# XN11EXXX register map
File version: 1.3
CPU: CM0 r0p0, little endian, no MPU, no FPU, 2 interrupt priority bits
Registers are 32-bit, read-write, reset 0x0 unless marked. A register's access mark holds for its fields unless they carry their own. Offsets are from the block's base; [hi:lo] are bit positions; {n}, {i} and the like mark numbered series.

## ADC — Analog-to-Digital Converter
Base 0x40020000
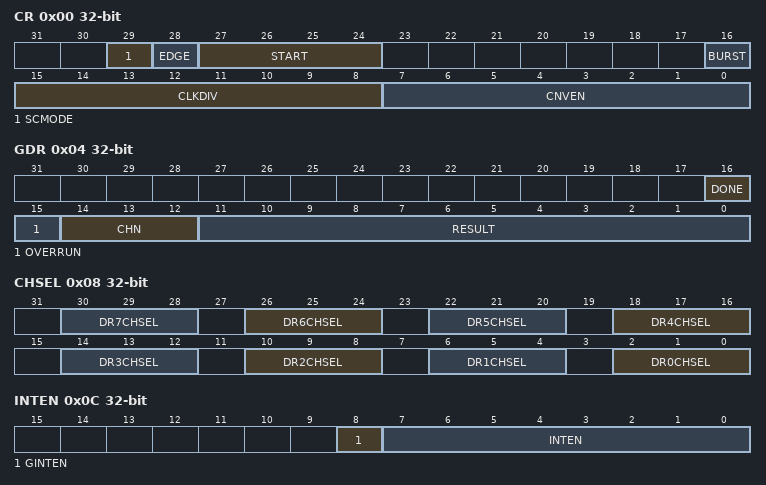
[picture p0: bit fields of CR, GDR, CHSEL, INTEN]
0x00 CR — ADC control register
  [29] SCMODE — ADC converter sample clock selection
  [28] EDGE — Start Edge control
  [27:24] START — Conversion starts control
  [16] BURST — Burst mode control
  [15:8] CLKDIV — APB clock (PCLK) divider
  [7:0] CNVEN — Enable ADC conversion value to DR0~DR7
0x04 GDR — ADC Global Data Register
  [16] DONE — This bit is set to 1 when an A/D conversion completes
  [15] OVERRUN — The conversion results has been overwritten
  [14:12] CHN — The ADC channel related to results
  [11:0] RESULT — Current ADC conversion results
0x08 CHSEL — Channel select control register
  [4n+2:4n] DR{n}CHSEL (n=0..7) — The conversion result is saved in DR{n} register
0x0C INTEN — ADC Interrupt Enable Register
  [8] GINTEN — enables the global DONE flag in ADC DR to generate an interrupt.
  [7:0] INTEN — These bits allow control over which A/D channels generate interrupts for conversion completion.
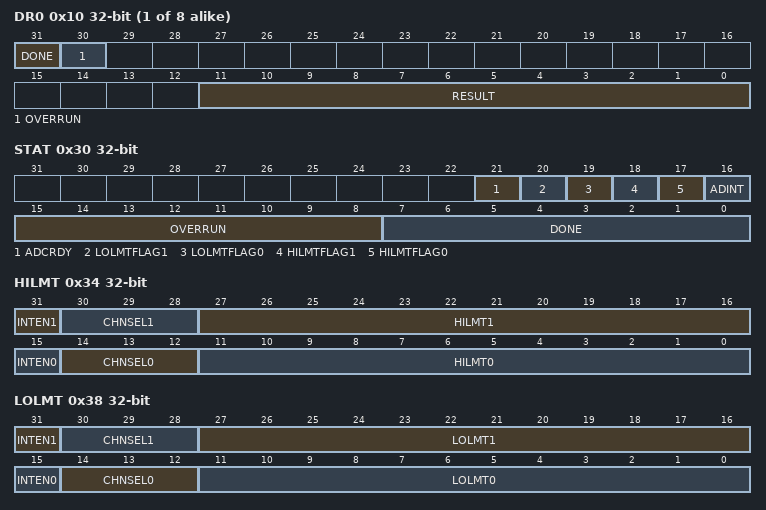
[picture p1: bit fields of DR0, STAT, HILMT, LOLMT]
{0x10+4i} DR{i} (i=0..7) — A/D Channel {i} Data Register
  [31] DONE — This bit is set to 1 when an A/D conversion completes
  [30] OVERRUN — Conversion results overwritten
  [11:0] RESULT — Conversion results
0x30 STAT — ADC Status Register
  [21] ADCRDY — ADC converter is ready to use
  [20] LOLMTFLAG1 — Low limit 1 status
  [19] LOLMTFLAG0 — Low limit 0 status
  [18] HILMTFLAG1 — High limit 1 status
  [17] HILMTFLAG0 — Low limit 0 status
  [16] ADINT — A/D interrupt flag
  [15:8] OVERRUN — These bits mirror the OVERRRUN status flags that appear in the result register for each A/D channel.
  [7:0] DONE — These bits mirror the DONE status flags that appear in the result register for each A/D channel.
0x34 HILMT — ADC High Limit Control Register
  [31] INTEN1 — Enable interrupt for High Limit value 1
  [30:28] CHNSEL1 — Select which channel to compare with the high limit value 1
  [27:16] HILMT1 — High Limit value 1
  [15] INTEN0 — Enable interrupt for High Limit value 0
  [14:12] CHNSEL0 — Select which channel to compare with the high limit value 0
  [11:0] HILMT0 — High Limit value 0
0x38 LOLMT — ADC Low Limit Control Register
  [31] INTEN1 — Enable interrupt for Low Limit value 1
  [30:28] CHNSEL1 — Select which channel to compare with the low limit value 1
  [27:16] LOLMT1 — Low Limit value 1
  [15] INTEN0 — Enable interrupt for Low Limit value 0
  [14:12] CHNSEL0 — Select which channel to compare with the low limit value 0
  [11:0] LOLMT0 — Low Limit value 0
0x40 SSCR — ADC software trigger convert register
  [0] ADCTRIG — Trigger ADC to do one time conversion
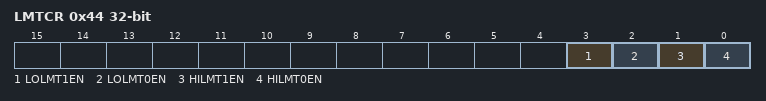
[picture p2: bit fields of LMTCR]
0x44 LMTCR — ADC Limit detection output enable control register
  [3] LOLMT1EN — Enable low limit 0 output to PWM fault
  [2] LOLMT0EN — Enable low limit 0 output to PWM fault
  [1] HILMT1EN — Enable high limit 1 output to PWM fault
  [0] HILMT0EN — Enable high limit 0 output to PWM fault

## PMU — Power management unit
Base 0x40038000
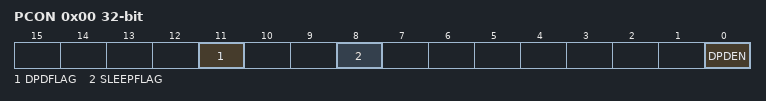
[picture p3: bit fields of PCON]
0x00 PCON — Power control register
  [11] DPDFLAG — Power-down flag
  [8] SLEEPFLAG — Sleep mode flag
  [0] DPDEN — Power-down mode enable

## SPI — Serial peripheral interface
Base 0x40040000
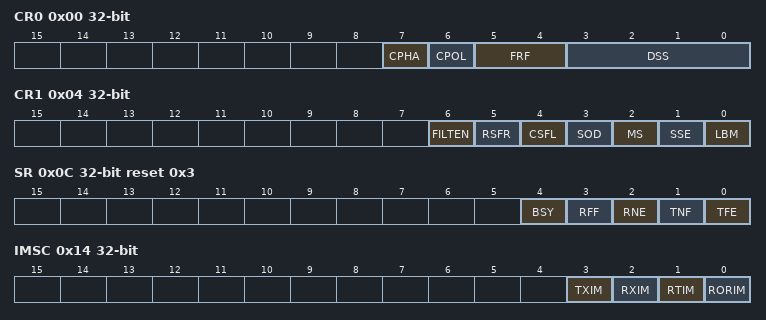
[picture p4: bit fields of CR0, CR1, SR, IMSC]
0x00 CR0 — SPI control register0
  [7] CPHA — Clock Out Phase
  [6] CPOL — Clock Out Polarity
  [5:4] FRF — Frame Format
  [3:0] DSS — Data Size Select
0x04 CR1 — SPI control register1
  [6] FILTEN — Enable SPI data line filter
  [5] RSFR — Clear receive FIFO
  [4] CSFL — SSEL control
  [3] SOD — Slave Output Disable
  [2] MS — Master/Slave Mode
  [1] SSE — SPI Enable
  [0] LBM — Loop Back Mode
0x08 DR — SPI data register
  [15:0] DATA
0x0C SR ro reset 0x3 — SPI status register
  [4] BSY — Busy
  [3] RFF — Receive FIFO Full
  [2] RNE — Receive FIFO Not Empty
  [1] TNF — Transmit FIFO Not Full
  [0] TFE — Transmit FIFO Empty
0x10 CPSR — SPI Clock Prescale Register
  [7:0] CPSDVSR
0x14 IMSC — SPI Interrupt Mask Set and Clear Register
  [3] TXIM — Software should set this bit to enable interrupt when the Tx FIFO is at least half empty.
  [2] RXIM — Software should set this bit to enable interrupt when the Rx FIFO is at least half full
  [1] RTIM — Software should set this bit to enable interrupt when a Receive Time-out condition occurs
  [0] RORIM — Software should set this bit to enable interrupt when a Receive Overrun occurs
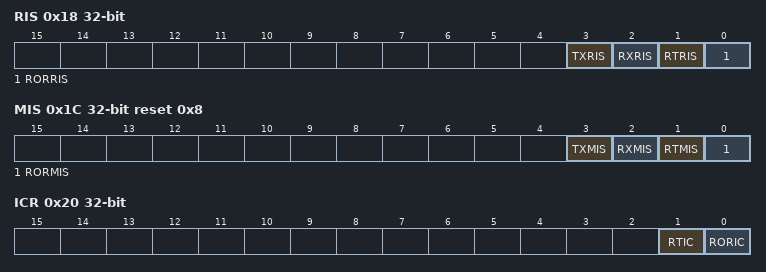
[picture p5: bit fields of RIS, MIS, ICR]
0x18 RIS ro — Raw Interrupt Status Register
  [3] TXRIS — This bit is 1 if the Tx FIFO is at least half empty.
  [2] RXRIS — This bit is 1 if the Rx FIFO is at least half full
  [1] RTRIS — This bit is 1 if the Rx FIFO is not empty, and has not been read for a time-out period
  [0] RORRIS — This bit is 1 if another frame was completely received while the Rx FIFO was full
0x1C MIS ro reset 0x8 — Masked Interrupt Status Register
  [3] TXMIS — This bit is 1 if the Tx FIFO is at least half empty, and this interrupt is enabled
  [2] RXMIS — This bit is 1 if the Rx FIFO is at least half full, and this interrupt is enabled
  [1] RTMIS — This bit is 1 if the Rx FIFO is not empty, has not been read for a time-out period, and this interrupt is enabled.
  [0] RORMIS — This bit is 1 if another frame was completely received while the RxFIFO was full, and this interrupt is enabled
0x20 ICR wo — SPI Interrupt Clear Register
  [1] RTIC — Writing a 1 to this bit clears the Rx FIFO was not empty and has not been read for a time-out period interrupt
  [0] RORIC — Writing a 1 to this bit clears the frame was received when Rx FIFO was full interrupt
